# C2C-Slave_NIU_Firewall register map
Vendor: Texas Instruments
Peripheral module from a debugger description file (folder omap4460).
Registers are 32-bit, read-write, no defined reset value unless marked. A register's access mark holds for its fields unless they carry their own. Offsets are as the file gives them; lines under a group give offsets from that group; [hi:lo] are bit positions; {n}, {i} and the like mark numbered series; 'fields as' and 'values as' point back to an identical list; <NAME> marks a mode.

## C2C-Slave_NIU_Firewall
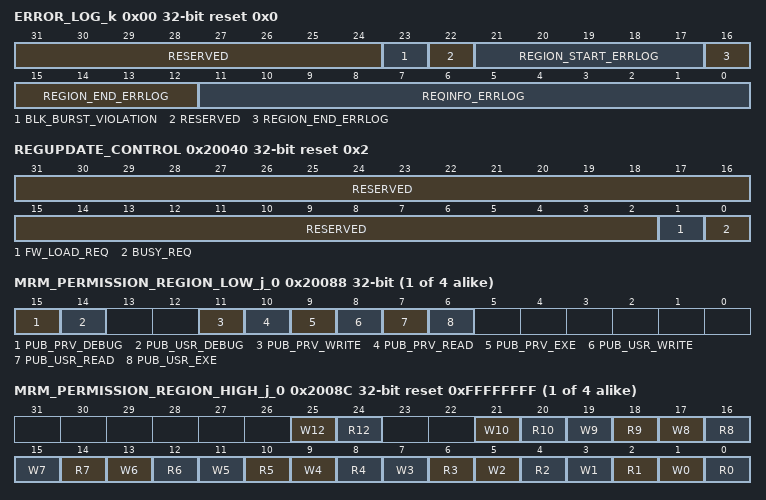
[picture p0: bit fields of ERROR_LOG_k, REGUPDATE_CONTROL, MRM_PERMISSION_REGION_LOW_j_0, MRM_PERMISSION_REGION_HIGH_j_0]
0x00 ERROR_LOG_k access per field reset 0x0 — Error log register for port k
  [31:24] RESERVED ro — Reads return 0s.
  [23] BLK_BURST_VIOLATION rw — Read 0x1: 2D burst not allowed or exceeding allowed size Write to clear ERROR_LOG_k and LOGICAL_ADDR_ERRLOG_k registers
  [22] RESERVED ro — Reads return 0s.
  [21:17] REGION_START_ERRLOG rw — Read: Wrong access hit this region number Write to clear ERROR_LOG_k and LOGICAL_ADDR_ERRLOG_k registers
  [16:12] REGION_END_ERRLOG rw — Read: Wrong access hit this region number Write to clear ERROR_LOG_k and LOGICAL_ADDR_ERRLOG_k registers
  [11:0] REQINFO_ERRLOG rw — Read: Error in reqinfo vector mapped as follows: [11: 8] ConnID [3:0] [7] MCMD [0] [6:4] Reserved [3] MReqDebug [2] Reserved [1] MReqSupervisor [0] MReqType Write to clear ERROR_LOG_k and LOGICAL_ADDR_ERRLOG_k registers
0x20004 LOGICAL_ADDR_ERRLOG_k ro reset 0x0 — Logical Physical Address Error log register for port k
  [31:0] SLVOFS_LOGICAL — Address generated by the Initiator before being translated
0x20040 REGUPDATE_CONTROL access per field reset 0x2 — Register update control register
  [31:2] RESERVED ro — Reads return 0s.
  [1] FW_LOAD_REQ ro — Hadrdware set/Software clear
  [0] BUSY_REQ rw — Busy request
{0x20088+0x10*i} MRM_PERMISSION_REGION_LOW_j_{i} (i=0..3) — Region j Permission Low
  [15] PUB_PRV_DEBUG — Public Privilege Debug Allowed
  [14] PUB_USR_DEBUG — Public User Debug Allowed
  [11] PUB_PRV_WRITE — Public Privilege Write Allowed
  [10] PUB_PRV_READ — Public Privilege Read Allowed
  [9] PUB_PRV_EXE — Public Privilege Exe Allowed
  [8] PUB_USR_WRITE — Public User Write Access Allowed
  [7] PUB_USR_READ — Public User Read Access Allowed
  [6] PUB_USR_EXE — Public User Exe Access Allowed
{0x2008C+0x10*i} MRM_PERMISSION_REGION_HIGH_j_{i} reset 0xFFFFFFFF (i=0..3) — Region j Permission High
  [25] W12 — Master NIU ConnID = 12 write permission
  [24] R12 — Master NIU ConnID = 12 read permission
  [2n+1] W{n} (n=0..10) — Master NIU ConnID = {n} write permission
  [2n] R{n} (n=0..10) — Master NIU ConnID = {n} read permission
